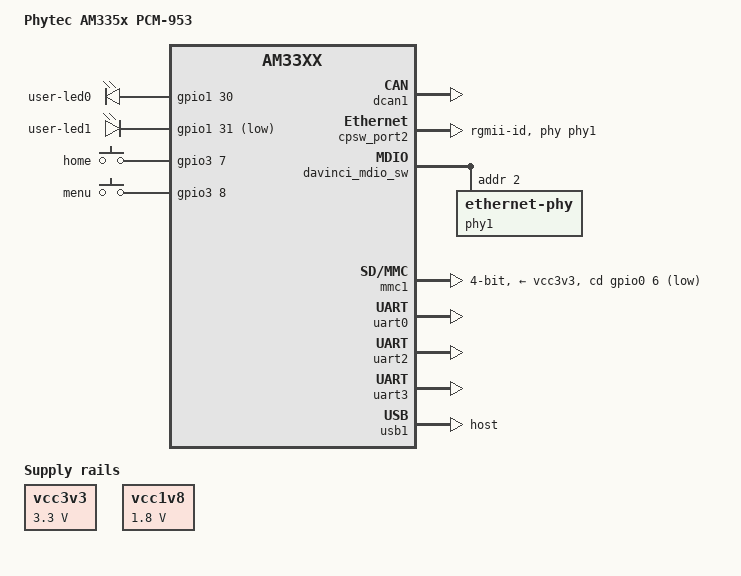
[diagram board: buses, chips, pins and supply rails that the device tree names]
#include <dt-bindings/input/input.h>
/ {
	model = "Phytec AM335x PCM-953";
	compatible = "phytec,am335x-pcm-953", "phytec,am335x-phycore-som", "ti,am33xx";
	vcc3v3: fixedregulator1 {
		compatible = "regulator-fixed";
		regulator-name = "vcc3v3";
		regulator-min-microvolt = <3300000>;
		regulator-max-microvolt = <3300000>;
		regulator-boot-on;
	};
	vcc1v8: fixedregulator2 {
		compatible = "regulator-fixed";
		regulator-name = "vcc1v8";
		regulator-min-microvolt = <1800000>;
		regulator-max-microvolt = <1800000>;
		regulator-boot-on;
	};
	user_leds: user-leds {
		compatible = "gpio-leds";
		pinctrl-names = "default";
		pinctrl-0 = <&user_leds_pins>;
		user-led0 {
			gpios = <&gpio1 30 GPIO_ACTIVE_HIGH>;
			default-state = "on";
		};
		user-led1 {
			gpios = <&gpio1 31 GPIO_ACTIVE_LOW>;
			default-state = "on";
		};
	};
	user_buttons: user-buttons {
		compatible = "gpio-keys";
		pinctrl-names = "default";
		pinctrl-0 = <&user_buttons_pins>;
		button-0 {
			label = "home";
			linux,code = <KEY_HOME>;
			gpios = <&gpio3 7 GPIO_ACTIVE_HIGH>;
			wakeup-source;
		};
		button-1 {
			label = "menu";
			linux,code = <KEY_MENU>;
			gpios = <&gpio3 8 GPIO_ACTIVE_HIGH>;
			wakeup-source;
		};
	};
};
&am33xx_pinmux {
	user_buttons_pins: pinmux-user-buttons-pins {
		pinctrl-single,pins = <
			AM33XX_PADCONF(AM335X_PIN_EMU0, PIN_INPUT_PULLDOWN, MUX_MODE7)	 
			AM33XX_PADCONF(AM335X_PIN_EMU1, PIN_INPUT_PULLDOWN, MUX_MODE7)	 
		>;
	};
	user_leds_pins: pinmux-user-leds-pins {
		pinctrl-single,pins = <
			AM33XX_PADCONF(AM335X_PIN_GPMC_CSN1, PIN_OUTPUT_PULLDOWN, MUX_MODE7)	 
			AM33XX_PADCONF(AM335X_PIN_GPMC_CSN2, PIN_OUTPUT_PULLDOWN, MUX_MODE7)	 
		>;
	};
};
&am33xx_pinmux {
	dcan1_pins: pinmux-dcan1-pins {
		pinctrl-single,pins = <
			AM33XX_PADCONF(AM335X_PIN_UART1_RXD, PIN_OUTPUT_PULLUP, MUX_MODE2)	 
			AM33XX_PADCONF(AM335X_PIN_UART1_TXD, PIN_INPUT_PULLUP, MUX_MODE2)	 
		>;
	};
};
&dcan1 {
	pinctrl-names = "default";
	pinctrl-0 = <&dcan1_pins>;
	status = "okay";
};
&am33xx_pinmux {
	ethernet1_pins: ethernet1-pins {
		pinctrl-single,pins = <
			AM33XX_PADCONF(AM335X_PIN_GPMC_A0, PIN_OUTPUT_PULLDOWN, MUX_MODE2)	 
			AM33XX_PADCONF(AM335X_PIN_GPMC_A1, PIN_INPUT_PULLDOWN, MUX_MODE2)	 
			AM33XX_PADCONF(AM335X_PIN_GPMC_A2, PIN_OUTPUT_PULLDOWN, MUX_MODE2)	 
			AM33XX_PADCONF(AM335X_PIN_GPMC_A3, PIN_OUTPUT_PULLDOWN, MUX_MODE2)	 
			AM33XX_PADCONF(AM335X_PIN_GPMC_A4, PIN_OUTPUT_PULLDOWN, MUX_MODE2)	 
			AM33XX_PADCONF(AM335X_PIN_GPMC_A5, PIN_OUTPUT_PULLDOWN, MUX_MODE2)	 
			AM33XX_PADCONF(AM335X_PIN_GPMC_A6, PIN_OUTPUT_PULLDOWN, MUX_MODE2)	 
			AM33XX_PADCONF(AM335X_PIN_GPMC_A7, PIN_INPUT_PULLDOWN, MUX_MODE2)	 
			AM33XX_PADCONF(AM335X_PIN_GPMC_A8, PIN_INPUT_PULLDOWN, MUX_MODE2)	 
			AM33XX_PADCONF(AM335X_PIN_GPMC_A9, PIN_INPUT_PULLDOWN, MUX_MODE2)	 
			AM33XX_PADCONF(AM335X_PIN_GPMC_A10, PIN_INPUT_PULLDOWN, MUX_MODE2)	 
			AM33XX_PADCONF(AM335X_PIN_GPMC_A11, PIN_INPUT_PULLDOWN, MUX_MODE2)	 
		>;
	};
};
&cpsw_port2 {
	phy-handle = <&phy1>;
	phy-mode = "rgmii-id";
	ti,dual-emac-pvid = <2>;
	status = "okay";
};
&davinci_mdio_sw {
	phy1: ethernet-phy@2 {
		reg = <2>;
	};
};
&mac_sw {
	pinctrl-names = "default";
	pinctrl-0 = <&ethernet0_pins &ethernet1_pins>;
};
&am33xx_pinmux {
	pinctrl-names = "default";
	pinctrl-0 = <&cb_gpio_pins>;
	cb_gpio_pins: pinmux-cb-gpio-pins {
		pinctrl-single,pins = <
			AM33XX_PADCONF(AM335X_PIN_UART0_CTSN, PIN_OUTPUT_PULLDOWN, MUX_MODE7)	 
			AM33XX_PADCONF(AM335X_PIN_UART0_RTSN, PIN_OUTPUT_PULLDOWN, MUX_MODE7)	 
		>;
	};
};
&am33xx_pinmux {
	mmc1_pins: pinmux-mmc1-pins {
		pinctrl-single,pins = <
			AM33XX_PADCONF(AM335X_PIN_MMC0_DAT3, PIN_INPUT_PULLUP, MUX_MODE0)
			AM33XX_PADCONF(AM335X_PIN_MMC0_DAT2, PIN_INPUT_PULLUP, MUX_MODE0)
			AM33XX_PADCONF(AM335X_PIN_MMC0_DAT1, PIN_INPUT_PULLUP, MUX_MODE0)
			AM33XX_PADCONF(AM335X_PIN_MMC0_DAT0, PIN_INPUT_PULLUP, MUX_MODE0)
			AM33XX_PADCONF(AM335X_PIN_MMC0_CLK, PIN_INPUT_PULLUP, MUX_MODE0)
			AM33XX_PADCONF(AM335X_PIN_MMC0_CMD, PIN_INPUT_PULLUP, MUX_MODE0)
			AM33XX_PADCONF(AM335X_PIN_SPI0_CS1, PIN_INPUT_PULLUP, MUX_MODE7)	 
		>;
	};
};
&mmc1 {
	vmmc-supply = <&vcc3v3>;
	bus-width = <4>;
	pinctrl-names = "default";
	pinctrl-0 = <&mmc1_pins>;
	cd-gpios = <&gpio0 6 GPIO_ACTIVE_LOW>;
	status = "okay";
};
&am33xx_pinmux {
	uart0_pins: pinmux-uart0-pins {
		pinctrl-single,pins = <
			AM33XX_PADCONF(AM335X_PIN_UART0_RXD, PIN_INPUT_PULLUP, MUX_MODE0)
			AM33XX_PADCONF(AM335X_PIN_UART0_TXD, PIN_OUTPUT_PULLDOWN, MUX_MODE0)
		>;
	};
	uart1_pins: pinmux-uart1-pins {
		pinctrl-single,pins = <
			AM33XX_PADCONF(AM335X_PIN_UART1_RXD, PIN_INPUT_PULLUP, MUX_MODE0)
			AM33XX_PADCONF(AM335X_PIN_UART1_TXD, PIN_OUTPUT_PULLDOWN, MUX_MODE0)
			AM33XX_PADCONF(AM335X_PIN_UART1_CTSN, PIN_INPUT, MUX_MODE0)
			AM33XX_PADCONF(AM335X_PIN_UART1_RTSN, PIN_OUTPUT_PULLDOWN, MUX_MODE0)
		>;
	};
	uart2_pins: pinmux-uart2-pins {
		pinctrl-single,pins = <
			AM33XX_PADCONF(AM335X_PIN_MII1_TX_CLK, PIN_INPUT_PULLUP, MUX_MODE1)	 
			AM33XX_PADCONF(AM335X_PIN_MII1_RX_CLK, PIN_OUTPUT_PULLDOWN, MUX_MODE1)	 
		>;
	};
	uart3_pins: pinmux-uart3-pins {
		pinctrl-single,pins = <
			AM33XX_PADCONF(AM335X_PIN_MII1_RXD3, PIN_INPUT_PULLUP, MUX_MODE1)	 
			AM33XX_PADCONF(AM335X_PIN_MII1_RXD2, PIN_OUTPUT_PULLDOWN, MUX_MODE1)	 
		>;
	};
};
&uart0 {
	pinctrl-names = "default";
	pinctrl-0 = <&uart0_pins>;
	status = "okay";
};
&uart1 {
	pinctrl-names = "default";
	pinctrl-0 = <&uart1_pins>;
};
&uart2 {
	pinctrl-names = "default";
	pinctrl-0 = <&uart2_pins>;
	status = "okay";
};
&uart3 {
	pinctrl-names = "default";
	pinctrl-0 = <&uart3_pins>;
	status = "okay";
};
&usb1 {
	dr_mode = "host";
};
